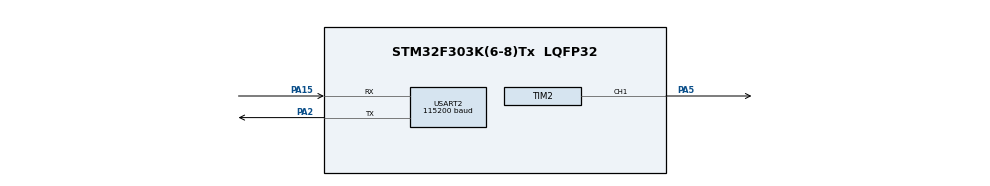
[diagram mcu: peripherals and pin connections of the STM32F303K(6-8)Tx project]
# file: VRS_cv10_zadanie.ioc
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Dma.Request0=USART2_RX
Dma.Request1=USART2_TX
Dma.USART2_RX.0.Direction=DMA_PERIPH_TO_MEMORY
Dma.USART2_RX.0.Instance=DMA1_Channel6
Dma.USART2_RX.0.MemDataAlignment=DMA_MDATAALIGN_BYTE
Dma.USART2_RX.0.MemInc=DMA_MINC_ENABLE
Dma.USART2_RX.0.Mode=DMA_CIRCULAR
Dma.USART2_RX.0.PeriphDataAlignment=DMA_PDATAALIGN_BYTE
Dma.USART2_RX.0.PeriphInc=DMA_PINC_DISABLE
Dma.USART2_RX.0.Priority=DMA_PRIORITY_MEDIUM
Dma.USART2_TX.1.Direction=DMA_MEMORY_TO_PERIPH
Dma.USART2_TX.1.Instance=DMA1_Channel7
Dma.USART2_TX.1.MemDataAlignment=DMA_MDATAALIGN_BYTE
Dma.USART2_TX.1.MemInc=DMA_MINC_ENABLE
Dma.USART2_TX.1.Mode=DMA_NORMAL
Dma.USART2_TX.1.PeriphDataAlignment=DMA_PDATAALIGN_BYTE
Dma.USART2_TX.1.PeriphInc=DMA_PINC_DISABLE
Dma.USART2_TX.1.Priority=DMA_PRIORITY_MEDIUM
Mcu.Family=STM32F3
Mcu.Name=STM32F303K(6-8)Tx
Mcu.Package=LQFP32
NVIC.DMA1_Channel6_IRQn=true\:0\:0\:false\:false\:true\:false\:true
NVIC.DMA1_Channel7_IRQn=true\:0\:0\:false\:false\:true\:false\:true
NVIC.PriorityGroup=NVIC_PRIORITYGROUP_4
NVIC.TIM2_IRQn=true\:0\:0\:false\:false\:true\:true\:true
NVIC.USART2_IRQn=true\:0\:0\:false\:false\:true\:true\:true
PA15.Mode=Asynchronous
PA15.Signal=USART2_RX
PA2.Mode=Asynchronous
PA2.Signal=USART2_TX
PA5.Signal=S_TIM2_CH1_ETR
ProjectManager.HeapSize=0x200
ProjectManager.StackSize=0x400
ProjectManager.TargetToolchain=STM32CubeIDE
RCC.AHBFreq_Value=8000000
RCC.APB1Freq_Value=8000000
RCC.APB2Freq_Value=8000000
RCC.CortexFreq_Value=8000000
RCC.HSE_VALUE=8000000
RCC.HSI_VALUE=8000000
RCC.SYSCLKFreq_VALUE=8000000
SH.S_TIM2_CH1_ETR.0=TIM2_CH1,PWM Generation1 CH1
TIM2.Channel-Output\ Compare2\ No\ Output=TIM_CHANNEL_2
TIM2.Channel-PWM\ Generation1\ CH1=TIM_CHANNEL_1
TIM2.Period=99
TIM2.Prescaler=799
TIM2.Pulse-PWM\ Generation1\ CH1=50
USART2.BaudRate=115200
USART2.VirtualMode-Asynchronous=VM_ASYNC
USART2.WordLength=WORDLENGTH_8B
VP_TIM2_VS_ClockSourceINT.Mode=Internal
VP_TIM2_VS_no_output2.Mode=Output Compare2 No Output
board=NUCLEO-F303K8

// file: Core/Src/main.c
/* USER CODE BEGIN Header */
/**
  ******************************************************************************
  * @file           : main.c
  * @brief          : Main program body
  ******************************************************************************
  * @attention
  *
  * <h2><center>&copy; Copyright (c) 2021 STMicroelectronics.
  * All rights reserved.</center></h2>
  *
  * This software component is licensed by ST under BSD 3-Clause license,
  * the "License"; You may not use this file except in compliance with the
  * License. You may obtain a copy of the License at:
  *                        opensource.org/licenses/BSD-3-Clause
  *
  ******************************************************************************
  */
/* USER CODE END Header */
#include "main.h"
#include "dma.h"
#include "tim.h"
#include "usart.h"
#include "gpio.h"

/* USER CODE BEGIN Includes */
#include <stdio.h>
#include <stdlib.h>
#include <string.h>
#include <stdbool.h>

/* USER CODE END Includes */

/* USER CODE BEGIN PV */
uint8_t mode = 1;
uint8_t dutyCycle = 100;
uint8_t wantedDutyCycle = 0;
uint8_t fadeMode = 0;
/* USER CODE END PV */

void SystemClock_Config(void);
/* USER CODE BEGIN PFP */
void proccesDmaData(uint8_t* sign,uint16_t len);
void sendData(uint8_t* data,uint16_t len);
void pwmToLed(uint8_t* sign,uint16_t len);
void changeMode(uint8_t newMode);
void setDutyCycle(uint8_t D);
/* USER CODE END PFP */

int main(void)
{

  /* MCU Configuration--------------------------------------------------------*/

  /* Reset of all peripherals, Initializes the Flash interface and the Systick. */

  LL_APB2_GRP1_EnableClock(LL_APB2_GRP1_PERIPH_SYSCFG);
  LL_APB1_GRP1_EnableClock(LL_APB1_GRP1_PERIPH_PWR);

  NVIC_SetPriorityGrouping(NVIC_PRIORITYGROUP_4);

  /* System interrupt init*/

  /* Configure the system clock */
  SystemClock_Config();

  /* Initialize all configured peripherals */
  MX_GPIO_Init();
  MX_DMA_Init();
  MX_TIM2_Init();
  MX_USART2_UART_Init();
  /* USER CODE BEGIN 2 */
  USART2_RegisterCallback(proccesDmaData);
  LL_TIM_EnableIT_CC2(TIM2);
  LL_TIM_EnableCounter(TIM2);
  LL_TIM_CC_EnableChannel(TIM2, LL_TIM_CHANNEL_CH1);
  LL_TIM_EnableCounter(TIM2);
  /* USER CODE END 2 */

  /* Infinite loop */
  while (1)
  {

  }
}

void SystemClock_Config(void)
{
  LL_FLASH_SetLatency(LL_FLASH_LATENCY_0);
  while(LL_FLASH_GetLatency()!= LL_FLASH_LATENCY_0)
  {
  }
  LL_RCC_HSI_Enable();

   /* Wait till HSI is ready */
  while(LL_RCC_HSI_IsReady() != 1)
  {

  }
  LL_RCC_HSI_SetCalibTrimming(16);
  LL_RCC_SetAHBPrescaler(LL_RCC_SYSCLK_DIV_1);
  LL_RCC_SetAPB1Prescaler(LL_RCC_APB1_DIV_1);
  LL_RCC_SetAPB2Prescaler(LL_RCC_APB2_DIV_1);
  LL_RCC_SetSysClkSource(LL_RCC_SYS_CLKSOURCE_HSI);

   /* Wait till System clock is ready */
  while(LL_RCC_GetSysClkSource() != LL_RCC_SYS_CLKSOURCE_STATUS_HSI)
  {

  }
  LL_Init1msTick(8000000);
  LL_SetSystemCoreClock(8000000);
}

/* USER CODE BEGIN 4 */
void proccesDmaData(uint8_t* sign,uint16_t len){
	uint8_t *tx_data;
	char str[len];
	for(int j=0;j<len;j++){
		str[j] = *(sign+j);
	}
	if(strstr(str,"$auto$")){
		changeMode(1);
	}
	else if(strstr(str,"$manual$")){
		changeMode(2);
	}
	else if(strstr(str,"$PWM")){
		pwmToLed(sign,len);
	}
	else{
		int len_data = asprintf(&tx_data, "\n\rInvalid command\n\rValid command:\n\r$auto$ - automatic mode\n\r$manual$ - manual mode\n\r$PWMxx$ - PWM settings in manual mode\n\rMode is %d - 1(automatic) 2(manual)\n\r",mode);
		sendData(tx_data,len_data);
		free(tx_data);
	}
}

void sendData(uint8_t* data,uint16_t len){
	USART2_PutBuffer(data, len);
}

void pwmToLed(uint8_t* sign,uint16_t len){
	uint8_t *tx_data;
	char str[len];
	for(int j=0;j<len;j++){
		str[j] = *(sign+j);
	}
	char breakset[] = "0123456789";
	if(strstr(str,"$PWM") && ((*(strpbrk(str, breakset)+1) == '$') || (*(strpbrk(str, breakset)+2) == '$') || (*(strpbrk(str, breakset)+3) == '$'))){
		wantedDutyCycle = atoi(strpbrk(str, breakset));
		int len_data = asprintf(&tx_data, "The brightness is set to: : %d %\n\r",wantedDutyCycle);
		sendData(tx_data,len_data);
		free(tx_data);
	}
	else{
		int len_data = asprintf(&tx_data, "End char '$' not found%\n\r");
		sendData(tx_data,len_data);
		free(tx_data);
	}
}

void changeMode(uint8_t newMode){
	uint8_t *tx_data;
	mode = newMode;
	if (newMode == 1){
		int len_data = asprintf(&tx_data, "Mode is set to:  automatic\n\r");
		sendData(tx_data,len_data);
		free(tx_data);
	}
	else if (newMode == 2){
		LL_mDelay(50);
		int len_data = asprintf(&tx_data, "Mode is set to:  manual\n\r");
		sendData(tx_data,len_data);
		free(tx_data);
	}
	else{
		int len_data = asprintf(&tx_data, "Mode is set to:  none\n\r");
		sendData(tx_data,len_data);
		free(tx_data);
	}
	return;
}

void changeLedPWM(){
	if(mode == 1){
		if(fadeMode == 0){
				dutyCycle -= 1;
				if(dutyCycle <= 0){
					fadeMode = 1;
				}
			}
			else if(fadeMode == 1){
				dutyCycle += 1;
				if (dutyCycle >= 100){
					fadeMode = 0;
				}
			}
	}
	else if(mode == 2){
		if(wantedDutyCycle < dutyCycle){
			dutyCycle -=1;
		}
		else if(wantedDutyCycle > dutyCycle){
			dutyCycle +=1;
		}
	}
	setDutyCycle(dutyCycle);
}

void setDutyCycle(uint8_t D){
	TIM2->CCR1 = ((TIM2->ARR) * D) / 100;
}

/* USER CODE END 4 */

void Error_Handler(void)
{
  __disable_irq();
  while (1)
  {
  }
}

/************************ (C) COPYRIGHT STMicroelectronics *****END OF FILE****/
